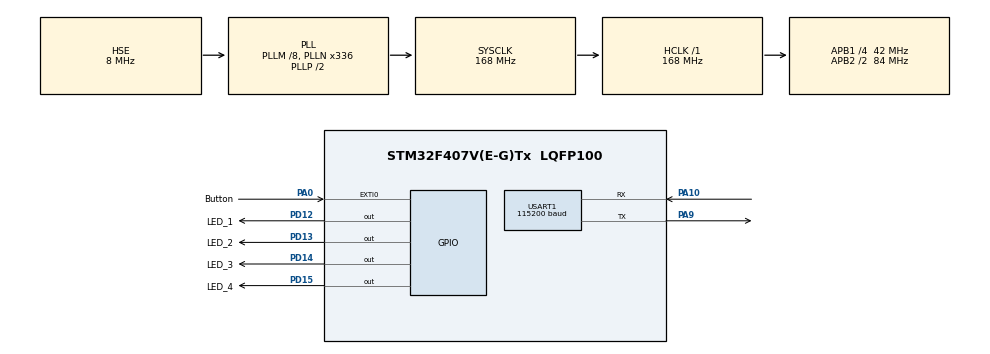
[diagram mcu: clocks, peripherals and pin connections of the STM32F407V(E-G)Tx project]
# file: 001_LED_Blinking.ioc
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Mcu.Family=STM32F4
Mcu.Name=STM32F407V(E-G)Tx
Mcu.Package=LQFP100
NVIC.PriorityGroup=NVIC_PRIORITYGROUP_0
PA0-WKUP.GPIO_Label=Button
PA0-WKUP.GPIO_ModeDefaultEXTI=GPIO_MODE_IT_RISING_FALLING
PA0-WKUP.GPIO_PuPd=GPIO_PULLUP
PA0-WKUP.Signal=GPXTI0
PA10.Mode=Asynchronous
PA10.Signal=USART1_RX
PA13.Mode=Trace_Asynchronous_SW
PA13.Signal=SYS_JTMS-SWDIO
PA14.Mode=Trace_Asynchronous_SW
PA14.Signal=SYS_JTCK-SWCLK
PA9.Mode=Asynchronous
PA9.Signal=USART1_TX
PB3.Mode=Trace_Asynchronous_SW
PB3.Signal=SYS_JTDO-SWO
PD12.GPIO_Label=LED_1
PD12.GPIO_ModeDefaultOutputPP=GPIO_MODE_OUTPUT_OD
PD12.GPIO_PuPd=GPIO_NOPULL
PD12.PinState=GPIO_PIN_SET
PD12.Signal=GPIO_Output
PD13.GPIO_Label=LED_2
PD13.Signal=GPIO_Output
PD14.GPIO_Label=LED_3
PD14.Signal=GPIO_Output
PD15.GPIO_Label=LED_4
PD15.Signal=GPIO_Output
PH0-OSC_IN.Mode=HSE-External-Oscillator
PH0-OSC_IN.Signal=RCC_OSC_IN
PH1-OSC_OUT.Mode=HSE-External-Oscillator
PH1-OSC_OUT.Signal=RCC_OSC_OUT
ProjectManager.HeapSize=0x200
ProjectManager.StackSize=0x400
ProjectManager.TargetToolchain=STM32CubeIDE
RCC.48MHZClocksFreq_Value=48000000
RCC.AHBFreq_Value=168000000
RCC.APB1CLKDivider=RCC_HCLK_DIV4
RCC.APB1Freq_Value=42000000
RCC.APB1TimFreq_Value=84000000
RCC.APB2CLKDivider=RCC_HCLK_DIV2
RCC.APB2Freq_Value=84000000
RCC.APB2TimFreq_Value=168000000
RCC.CortexFreq_Value=168000000
RCC.HCLKFreq_Value=168000000
RCC.HSE_VALUE=8000000
RCC.HSI_VALUE=16000000
RCC.LSE_VALUE=32768
RCC.PLLM=8
RCC.PLLN=336
RCC.PLLQ=7
RCC.PLLSourceVirtual=RCC_PLLSOURCE_HSE
RCC.SYSCLKFreq_VALUE=168000000
RCC.SYSCLKSource=RCC_SYSCLKSOURCE_PLLCLK
RCC.VCOOutputFreq_Value=336000000
USART1.BaudRate=115200
USART1.VirtualMode=VM_ASYNC
board=STM32F407G-DISC1

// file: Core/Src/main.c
/* USER CODE BEGIN Header */
/**
  ******************************************************************************
  * @file           : main.c
  * @brief          : Main program body
  ******************************************************************************
  * @attention
  *
  * Copyright (c) 2025 STMicroelectronics.
  * All rights reserved.
  *
  * This software is licensed under terms that can be found in the LICENSE file
  * in the root directory of this software component.
  * If no LICENSE file comes with this software, it is provided AS-IS.
  *
  ******************************************************************************
  */
/* USER CODE END Header */
#include "main.h"

/* USER CODE BEGIN Includes */

#include "stdio.h"

/* USER CODE END Includes */

UART_HandleTypeDef huart1;

void SystemClock_Config(void);
static void MX_GPIO_Init(void);
static void MX_USART1_UART_Init(void);

/* USER CODE BEGIN 0 */

// Send printf to uart1
int _write(int file, char *ptr, int len) {
  int DataIdx;
  for (DataIdx = 0; DataIdx < len; DataIdx++) {
    ITM_SendChar(*ptr++); // Mengirim karakter via ITM SWO
  }
  return len;
}

/* USER CODE END 0 */

int main(void)
{

  /* MCU Configuration--------------------------------------------------------*/

  /* Reset of all peripherals, Initializes the Flash interface and the Systick. */
  HAL_Init();

  /* Configure the system clock */
  SystemClock_Config();

  /* Initialize all configured peripherals */
  MX_GPIO_Init();
  MX_USART1_UART_Init();
  /* USER CODE BEGIN 2 */

  printf("First Application starting\n");

  /* USER CODE END 2 */

  /* Infinite loop */
  /* USER CODE BEGIN WHILE */

  uint32_t now = 0, last_print = 0;

  while (1)
  {
      now = HAL_GetTick();

      if (now - last_print >= 1000) {
          printf("Loop %lu\n", now);
          last_print = now;
      }

      // printf("Loop\n");
      // HAL_Delay(1000);
    /* USER CODE END WHILE */

  }
}

void SystemClock_Config(void)
{
  RCC_OscInitTypeDef RCC_OscInitStruct = {0};
  RCC_ClkInitTypeDef RCC_ClkInitStruct = {0};

  /** Configure the main internal regulator output voltage
  */
  __HAL_RCC_PWR_CLK_ENABLE();
  __HAL_PWR_VOLTAGESCALING_CONFIG(PWR_REGULATOR_VOLTAGE_SCALE1);

  /** Initializes the RCC Oscillators according to the specified parameters
  * in the RCC_OscInitTypeDef structure.
  */
  RCC_OscInitStruct.OscillatorType = RCC_OSCILLATORTYPE_HSE;
  RCC_OscInitStruct.HSEState = RCC_HSE_ON;
  RCC_OscInitStruct.PLL.PLLState = RCC_PLL_ON;
  RCC_OscInitStruct.PLL.PLLSource = RCC_PLLSOURCE_HSE;
  RCC_OscInitStruct.PLL.PLLM = 8;
  RCC_OscInitStruct.PLL.PLLN = 336;
  RCC_OscInitStruct.PLL.PLLP = RCC_PLLP_DIV2;
  RCC_OscInitStruct.PLL.PLLQ = 7;
  if (HAL_RCC_OscConfig(&RCC_OscInitStruct) != HAL_OK)
  {
    Error_Handler();
  }

  /** Initializes the CPU, AHB and APB buses clocks
  */
  RCC_ClkInitStruct.ClockType = RCC_CLOCKTYPE_HCLK|RCC_CLOCKTYPE_SYSCLK
                              |RCC_CLOCKTYPE_PCLK1|RCC_CLOCKTYPE_PCLK2;
  RCC_ClkInitStruct.SYSCLKSource = RCC_SYSCLKSOURCE_PLLCLK;
  RCC_ClkInitStruct.AHBCLKDivider = RCC_SYSCLK_DIV1;
  RCC_ClkInitStruct.APB1CLKDivider = RCC_HCLK_DIV4;
  RCC_ClkInitStruct.APB2CLKDivider = RCC_HCLK_DIV2;

  if (HAL_RCC_ClockConfig(&RCC_ClkInitStruct, FLASH_LATENCY_5) != HAL_OK)
  {
    Error_Handler();
  }
}

static void MX_USART1_UART_Init(void)
{

  huart1.Instance = USART1;
  huart1.Init.BaudRate = 115200;
  huart1.Init.WordLength = UART_WORDLENGTH_8B;
  huart1.Init.StopBits = UART_STOPBITS_1;
  huart1.Init.Parity = UART_PARITY_NONE;
  huart1.Init.Mode = UART_MODE_TX_RX;
  huart1.Init.HwFlowCtl = UART_HWCONTROL_NONE;
  huart1.Init.OverSampling = UART_OVERSAMPLING_16;
  if (HAL_UART_Init(&huart1) != HAL_OK)
  {
    Error_Handler();
  }

}

static void MX_GPIO_Init(void)
{
  GPIO_InitTypeDef GPIO_InitStruct = {0};

  /* GPIO Ports Clock Enable */
  __HAL_RCC_GPIOH_CLK_ENABLE();
  __HAL_RCC_GPIOA_CLK_ENABLE();
  __HAL_RCC_GPIOD_CLK_ENABLE();
  __HAL_RCC_GPIOB_CLK_ENABLE();

  /*Configure GPIO pin Output Level */
  HAL_GPIO_WritePin(LED_1_GPIO_Port, LED_1_Pin, GPIO_PIN_SET);

  /*Configure GPIO pin Output Level */
  HAL_GPIO_WritePin(GPIOD, LED_2_Pin|LED_3_Pin|LED_4_Pin, GPIO_PIN_RESET);

  /*Configure GPIO pin : Button_Pin */
  GPIO_InitStruct.Pin = Button_Pin;
  GPIO_InitStruct.Mode = GPIO_MODE_IT_RISING_FALLING;
  GPIO_InitStruct.Pull = GPIO_PULLUP;
  HAL_GPIO_Init(Button_GPIO_Port, &GPIO_InitStruct);

  /*Configure GPIO pin : LED_1_Pin */
  GPIO_InitStruct.Pin = LED_1_Pin;
  GPIO_InitStruct.Mode = GPIO_MODE_OUTPUT_OD;
  GPIO_InitStruct.Pull = GPIO_NOPULL;
  GPIO_InitStruct.Speed = GPIO_SPEED_FREQ_LOW;
  HAL_GPIO_Init(LED_1_GPIO_Port, &GPIO_InitStruct);

  /*Configure GPIO pins : LED_2_Pin LED_3_Pin LED_4_Pin */
  GPIO_InitStruct.Pin = LED_2_Pin|LED_3_Pin|LED_4_Pin;
  GPIO_InitStruct.Mode = GPIO_MODE_OUTPUT_PP;
  GPIO_InitStruct.Pull = GPIO_NOPULL;
  GPIO_InitStruct.Speed = GPIO_SPEED_FREQ_LOW;
  HAL_GPIO_Init(GPIOD, &GPIO_InitStruct);

}

void Error_Handler(void)
{
  __disable_irq();
  while (1)
  {
  }
}
